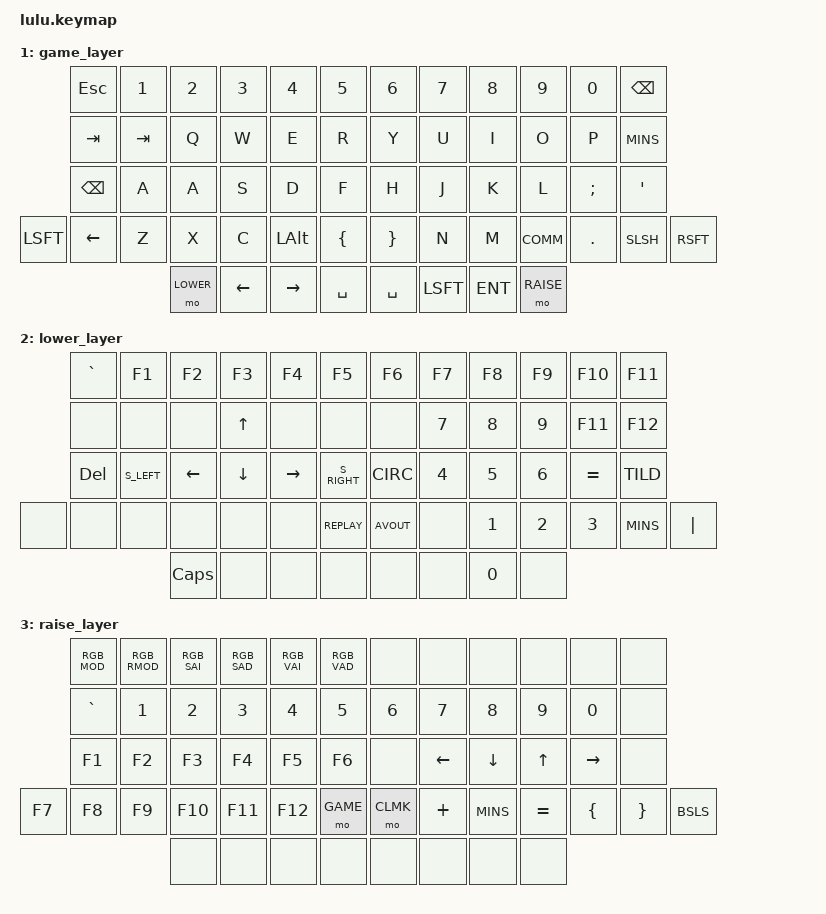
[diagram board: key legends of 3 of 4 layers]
# Lulu ZMK Keymap
# This is a starting point for converting your QMK Lulu keymap to ZMK format.
# Layers: Colemak, Game, Lower, Raise
# TODO: Fill in bindings based on QMK keymap.c

# Custom macro and tap-hold key mapping for Lulu
# S_LEFT: LCTL(KC_LEFT) → &kp LC(LEFT)
# S_RIGHT: LCTL(KC_RIGHT) → &kp LC(RIGHT)
# REPLAY: LCTL(LALT(KC_S)) → &kp LC(LA(S))
# AVOUT: LCTL(LALT(KC_F11)) → &kp LC(LA(F11))
# CT_SP: LCTL_T(KC_SPACE) → &ht CT_SP CTRL KC_SPACE
# T_TAB: Tap KC_T, Hold Ctrl+T → &ht T_TAB CTRL KC_T
# C_COPY: Tap KC_C, Hold Ctrl+C → &ht C_COPY CTRL KC_C
# V_PASTE: Tap KC_V, Hold Ctrl+V → &ht V_PASTE CTRL KC_V
# X_CUTT: Tap KC_X, Hold Ctrl+X → &ht X_CUTT CTRL KC_X
# (If ZMK does not support long-press macros natively, these may require custom behavior implementation.)
# Add custom behaviors to your ZMK config as needed.

keymap {
    compatible = "zmk,keymap";

    default_layer {
        bindings = <
            &kp ESC &kp 1 &kp 2 &kp 3 &kp 4 &kp 5 &kp 6 &kp 7 &kp 8 &kp 9 &kp 0 &kp BSPC
            &kp TAB &kp Q &kp W &kp F &kp P &kp B &kp J &kp L &kp U &kp Y &kp SCLN &kp DEL
            &kp BSPC &kp A &kp R &kp S &ht T_TAB T KC_T &kp G &kp M &kp N &kp E &kp I &kp O &kp QUOT
            &kp LSFT &kp Z &ht X_CUTT T KC_X &ht C_COPY T KC_C &kp D &ht V_PASTE T KC_V &kp LBRC &kp RBRC &kp K &kp H &kp COMM &kp DOT &kp SLSH &kp BSLS
            &kp LALT &kp LGUI &mo LOWER &mt CT_SP CTRL KC_SPACE &kp SPC &kp LSFT &kp ENT &mo RAISE
        >;
    };
    game_layer {
        bindings = <
            &kp ESC &kp 1 &kp 2 &kp 3 &kp 4 &kp 5 &kp 6 &kp 7 &kp 8 &kp 9 &kp 0 &kp BSPC
            &kp TAB &kp TAB &kp Q &kp W &kp E &kp R &kp Y &kp U &kp I &kp O &kp P &kp MINS
            &kp BSPC &kp A &kp A &kp S &kp D &kp F &kp H &kp J &kp K &kp L &kp SCLN &kp QUOT
            &kp LSFT &kp LEFT &kp Z &kp X &kp C &kp LALT &kp LBRC &kp RBRC &kp N &kp M &kp COMM &kp DOT &kp SLSH &kp RSFT
            &mo LOWER &kp LEFT &kp RIGHT &kp SPC &kp SPC &kp LSFT &kp ENT &mo RAISE
        >;
    };
    lower_layer {
        bindings = <
            &kp GRAVE &kp F1 &kp F2 &kp F3 &kp F4 &kp F5 &kp F6 &kp F7 &kp F8 &kp F9 &kp F10 &kp F11
            &none &none &none &kp UP &none &none &none &kp 7 &kp 8 &kp 9 &kp F11 &kp F12
            &kp DEL &kp S_LEFT &kp LEFT &kp DOWN &kp RIGHT &kp S_RIGHT &kp CIRC &kp 4 &kp 5 &kp 6 &kp EQL &kp TILD
            &none &none &none &none &none &none &kp REPLAY &kp AVOUT &none &kp 1 &kp 2 &kp 3 &kp MINS &kp PIPE
            &kp CAPS &none &none &none &none &none &kp 0 &none
        >;
    };
    raise_layer {
        bindings = <
            &kp RGB_MOD &kp RGB_RMOD &kp RGB_SAI &kp RGB_SAD &kp RGB_VAI &kp RGB_VAD &none &none &none &none &none &none
            &kp GRAVE &kp 1 &kp 2 &kp 3 &kp 4 &kp 5 &kp 6 &kp 7 &kp 8 &kp 9 &kp 0 &none
            &kp F1 &kp F2 &kp F3 &kp F4 &kp F5 &kp F6 &none &kp LEFT &kp DOWN &kp UP &kp RIGHT &none
            &kp F7 &kp F8 &kp F9 &kp F10 &kp F11 &kp F12 &mo GAME &mo CLMK &kp PLUS &kp MINS &kp EQL &kp LBRC &kp RBRC &kp BSLS
            &none &none &none &none &none &none &none &none
        >;
    };
}
